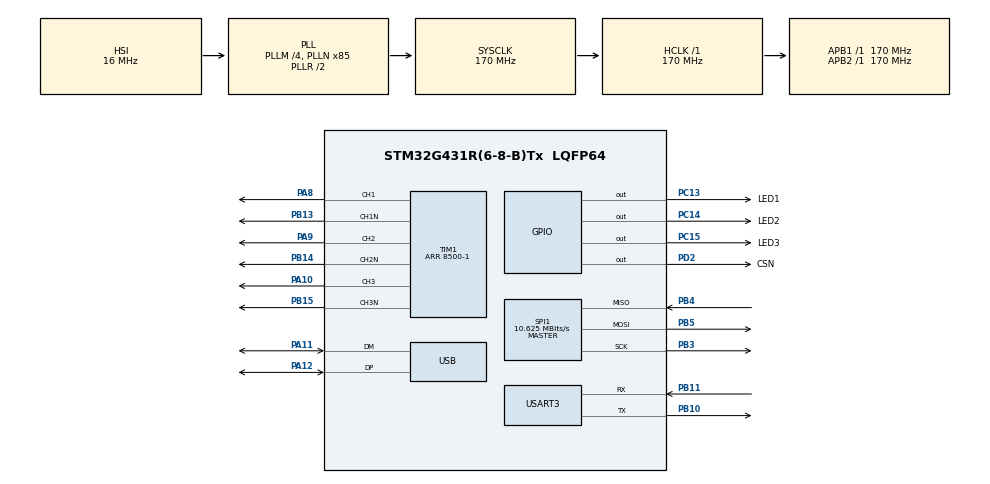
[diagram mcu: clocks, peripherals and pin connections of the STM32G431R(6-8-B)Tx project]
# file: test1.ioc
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Mcu.Family=STM32G4
Mcu.Name=STM32G431R(6-8-B)Tx
Mcu.Package=LQFP64
NVIC.PriorityGroup=NVIC_PRIORITYGROUP_4
NVIC.SPI1_IRQn=true\:0\:0\:false\:false\:true\:true\:true\:true
NVIC.TIM1_UP_TIM16_IRQn=true\:0\:0\:false\:false\:true\:true\:true\:true
NVIC.USB_LP_IRQn=true\:2\:0\:true\:false\:true\:true\:true\:true
PA10.Signal=S_TIM1_CH3
PA11.Mode=Device
PA11.Signal=USB_DM
PA12.Mode=Device
PA12.Signal=USB_DP
PA13.Mode=Serial_Wire
PA13.Signal=SYS_JTMS-SWDIO
PA14.Mode=Serial_Wire
PA14.Signal=SYS_JTCK-SWCLK
PA8.Signal=S_TIM1_CH1
PA9.Signal=S_TIM1_CH2
PB10.Mode=Asynchronous
PB10.Signal=USART3_TX
PB11.Mode=Asynchronous
PB11.Signal=USART3_RX
PB13.Mode=PWM Generation1 CH1 CH1N
PB13.Signal=TIM1_CH1N
PB14.Mode=PWM Generation2 CH2 CH2N
PB14.Signal=TIM1_CH2N
PB15.Mode=PWM Generation3 CH3 CH3N
PB15.Signal=TIM1_CH3N
PB3.Mode=Full_Duplex_Master
PB3.Signal=SPI1_SCK
PB4.Mode=Full_Duplex_Master
PB4.Signal=SPI1_MISO
PB5.Mode=Full_Duplex_Master
PB5.Signal=SPI1_MOSI
PC13.GPIO_Label=LED1
PC13.Signal=GPIO_Output
PC14-OSC32_IN.GPIO_Label=LED2
PC14-OSC32_IN.Signal=GPIO_Output
PC15-OSC32_OUT.GPIO_Label=LED3
PC15-OSC32_OUT.Signal=GPIO_Output
PD2.GPIO_Label=CSN
PD2.Signal=GPIO_Output
PF0-OSC_IN.Mode=HSE-External-Oscillator
PF0-OSC_IN.Signal=RCC_OSC_IN
PF1-OSC_OUT.Mode=HSE-External-Oscillator
PF1-OSC_OUT.Signal=RCC_OSC_OUT
ProjectManager.HeapSize=0x200
ProjectManager.StackSize=0x400
ProjectManager.TargetToolchain=MDK-ARM V5.32
RCC.ADC12Freq_Value=170000000
RCC.AHBFreq_Value=170000000
RCC.APB1Freq_Value=170000000
RCC.APB1TimFreq_Value=170000000
RCC.APB2Freq_Value=170000000
RCC.APB2TimFreq_Value=170000000
RCC.CK48CLockSelection=RCC_USBCLKSOURCE_HSI48
RCC.CortexFreq_Value=170000000
RCC.EXTERNAL_CLOCK_VALUE=12288000
RCC.HCLKFreq_Value=170000000
RCC.HSE_VALUE=8000000
RCC.HSI48_VALUE=48000000
RCC.HSI_VALUE=16000000
RCC.LSE_VALUE=32768
RCC.PLLM=RCC_PLLM_DIV4
RCC.PLLN=85
RCC.SYSCLKFreq_VALUE=170000000
RCC.SYSCLKSource=RCC_SYSCLKSOURCE_PLLCLK
RCC.USBFreq_Value=48000000
RCC.VCOOutputFreq_Value=340000000
SH.S_TIM1_CH1.0=TIM1_CH1,PWM Generation1 CH1 CH1N
SH.S_TIM1_CH2.0=TIM1_CH2,PWM Generation2 CH2 CH2N
SH.S_TIM1_CH3.0=TIM1_CH3,PWM Generation3 CH3 CH3N
SPI1.BaudRatePrescaler=SPI_BAUDRATEPRESCALER_16
SPI1.CLKPhase=SPI_PHASE_2EDGE
SPI1.CLKPolarity=SPI_POLARITY_HIGH
SPI1.CalculateBaudRate=10.625 MBits/s
SPI1.DataSize=SPI_DATASIZE_16BIT
SPI1.Direction=SPI_DIRECTION_2LINES
SPI1.Mode=SPI_MODE_MASTER
SPI1.VirtualType=VM_MASTER
STMicroelectronics.X-CUBE-ALGOBUILD.1.4.0.LibraryCcDSPOoLibraryJjDSPOoLibrary=true
TIM1.Channel-PWM\ Generation1\ CH1\ CH1N=TIM_CHANNEL_1
TIM1.Channel-PWM\ Generation2\ CH2\ CH2N=TIM_CHANNEL_2
TIM1.Channel-PWM\ Generation3\ CH3\ CH3N=TIM_CHANNEL_3
TIM1.PeriodNoDither=8500-1
TIM1.TIM_MasterOutputTrigger=TIM_TRGO_UPDATE
TIM1.TIM_MasterOutputTrigger2=TIM_TRGO2_UPDATE
USART3.VirtualMode-Asynchronous=VM_ASYNC
VP_STMicroelectronics.X-CUBE-ALGOBUILD_VS_DSPOoLibraryJjLibrary_1.4.0_1.4.0.Mode=DSPOoLibraryJjLibrary
VP_SYS_VS_DBSignals.Mode=DisableDeadBatterySignals
VP_TIM1_VS_ClockSourceINT.Mode=Internal
board=custom

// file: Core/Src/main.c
/* USER CODE BEGIN Header */
/**
  ******************************************************************************
  * @file           : main.c
  * @brief          : Main program body
  ******************************************************************************
  * @attention
  *
  * Copyright (c) 2026 STMicroelectronics.
  * All rights reserved.
  *
  * This software is licensed under terms that can be found in the LICENSE file
  * in the root directory of this software component.
  * If no LICENSE file comes with this software, it is provided AS-IS.
  *
  ******************************************************************************
  */
/* USER CODE END Header */
#include "main.h"
#include "spi.h"
#include "tim.h"
#include "usart.h"
#include "usb.h"
#include "gpio.h"

/* USER CODE BEGIN Includes */
#include "mt6816.h"
#include <bsp.h>
#include <debug.h>
#include "foc_app.h"
/* USER CODE END Includes */

/* USER CODE BEGIN PV */
float angle;
float mech_deg;
float elec_deg;
/* USER CODE END PV */

void SystemClock_Config(void);

int main(void)
{

  /* MCU Configuration--------------------------------------------------------*/

  /* Reset of all peripherals, Initializes the Flash interface and the Systick. */
  HAL_Init();

  /* Configure the system clock */
  SystemClock_Config();

  /* Initialize all configured peripherals */
  MX_GPIO_Init();
  MX_TIM1_Init();
  MX_USART3_UART_Init();
  MX_USB_PCD_Init();
  MX_SPI1_Init();
  /* USER CODE BEGIN 2 */
    debug_send("HALLO");
	MT6816_SPI_Signal_Init();
  FOC_Init();
  /* USER CODE END 2 */

  /* Infinite loop */
  while (1)
  {

    /* USER CODE BEGIN 3 */

		Debug_Task();
    HAL_Delay(1);
  }
  /* USER CODE END 3 */
}

void SystemClock_Config(void)
{
  RCC_OscInitTypeDef RCC_OscInitStruct = {0};
  RCC_ClkInitTypeDef RCC_ClkInitStruct = {0};

  /** Configure the main internal regulator output voltage
  */
  HAL_PWREx_ControlVoltageScaling(PWR_REGULATOR_VOLTAGE_SCALE1_BOOST);

  /** Initializes the RCC Oscillators according to the specified parameters
  * in the RCC_OscInitTypeDef structure.
  */
  RCC_OscInitStruct.OscillatorType = RCC_OSCILLATORTYPE_HSI|RCC_OSCILLATORTYPE_HSI48;
  RCC_OscInitStruct.HSIState = RCC_HSI_ON;
  RCC_OscInitStruct.HSICalibrationValue = RCC_HSICALIBRATION_DEFAULT;
  RCC_OscInitStruct.HSI48State = RCC_HSI48_ON;
  RCC_OscInitStruct.PLL.PLLState = RCC_PLL_ON;
  RCC_OscInitStruct.PLL.PLLSource = RCC_PLLSOURCE_HSI;
  RCC_OscInitStruct.PLL.PLLM = RCC_PLLM_DIV4;
  RCC_OscInitStruct.PLL.PLLN = 85;
  RCC_OscInitStruct.PLL.PLLP = RCC_PLLP_DIV2;
  RCC_OscInitStruct.PLL.PLLQ = RCC_PLLQ_DIV2;
  RCC_OscInitStruct.PLL.PLLR = RCC_PLLR_DIV2;
  if (HAL_RCC_OscConfig(&RCC_OscInitStruct) != HAL_OK)
  {
    Error_Handler();
  }

  /** Initializes the CPU, AHB and APB buses clocks
  */
  RCC_ClkInitStruct.ClockType = RCC_CLOCKTYPE_HCLK|RCC_CLOCKTYPE_SYSCLK
                              |RCC_CLOCKTYPE_PCLK1|RCC_CLOCKTYPE_PCLK2;
  RCC_ClkInitStruct.SYSCLKSource = RCC_SYSCLKSOURCE_PLLCLK;
  RCC_ClkInitStruct.AHBCLKDivider = RCC_SYSCLK_DIV1;
  RCC_ClkInitStruct.APB1CLKDivider = RCC_HCLK_DIV1;
  RCC_ClkInitStruct.APB2CLKDivider = RCC_HCLK_DIV1;

  if (HAL_RCC_ClockConfig(&RCC_ClkInitStruct, FLASH_LATENCY_4) != HAL_OK)
  {
    Error_Handler();
  }
}

void Error_Handler(void)
{
  __disable_irq();
  while (1)
  {
  }
}
